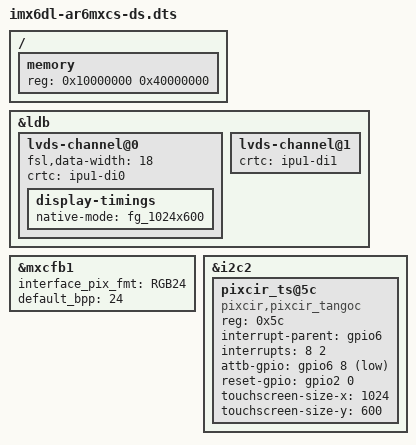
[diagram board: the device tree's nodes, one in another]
/*
 * Copyright (C) 2014 BCM Advanced Research
 *
 * This program is free software; you can redistribute it and/or modify
 * it under the terms of the GNU General Public License version 2 as
 * published by the Free Software Foundation.
 */

/dts-v1/;

#include "imx6dl.dtsi"
#include "imx6qdl-ar6mxcs.dtsi"
#include "imx6dl-ar6mxcs.dtsi"

/ {
	memory {
		reg = <0x10000000 0x40000000>;
	};
};

&ldb {
        lvds-channel@0 {
                fsl,data-width = <18>;
                crtc = "ipu1-di0";
                display-timings {
                        native-mode = <&fg_1024x600>;
                };
        };

        lvds-channel@1 {
                crtc = "ipu1-di1";
        };
};

&mxcfb1 {
        interface_pix_fmt = "RGB24";
        default_bpp = <24>;
};

&i2c2 {
	pixcir_ts@5c {
		compatible = "pixcir,pixcir_tangoc";
		reg = <0x5c>;
		interrupt-parent = <&gpio6>;
		interrupts = <8 2>;
		attb-gpio = <&gpio6 8 1>;
		reset-gpio = <&gpio2 0 0>;
		touchscreen-size-x = <1024>;
		touchscreen-size-y = <600>;
	};
};
